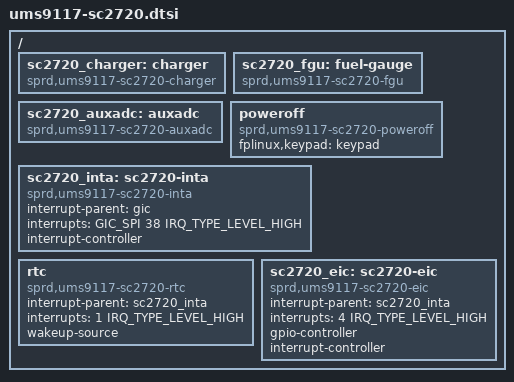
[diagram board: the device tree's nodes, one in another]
// SPDX-License-Identifier: GPL-2.0-only

/ {
	sc2720_charger: charger {
		compatible = "sprd,ums9117-sc2720-charger";
	};

	sc2720_fgu: fuel-gauge {
		compatible = "sprd,ums9117-sc2720-fgu";
	};

	sc2720_auxadc: auxadc {
		compatible = "sprd,ums9117-sc2720-auxadc";
	};

	poweroff {
		compatible = "sprd,ums9117-sc2720-poweroff";
		fplinux,keypad = <&keypad>;
	};

	sc2720_inta: sc2720-inta {
		compatible = "sprd,ums9117-sc2720-inta";
		interrupt-parent = <&gic>;
		interrupts = <GIC_SPI 38 IRQ_TYPE_LEVEL_HIGH>;
		interrupt-controller;
		#interrupt-cells = <2>;
	};

	rtc {
		compatible = "sprd,ums9117-sc2720-rtc";
		interrupt-parent = <&sc2720_inta>;
		interrupts = <1 IRQ_TYPE_LEVEL_HIGH>;
		interrupt-names = "alarm";
		wakeup-source;
	};

	sc2720_eic: sc2720-eic {
		compatible = "sprd,ums9117-sc2720-eic";
		interrupt-parent = <&sc2720_inta>;
		interrupts = <4 IRQ_TYPE_LEVEL_HIGH>;
		gpio-controller;
		#gpio-cells = <2>;
		interrupt-controller;
		#interrupt-cells = <2>;
	};
};
